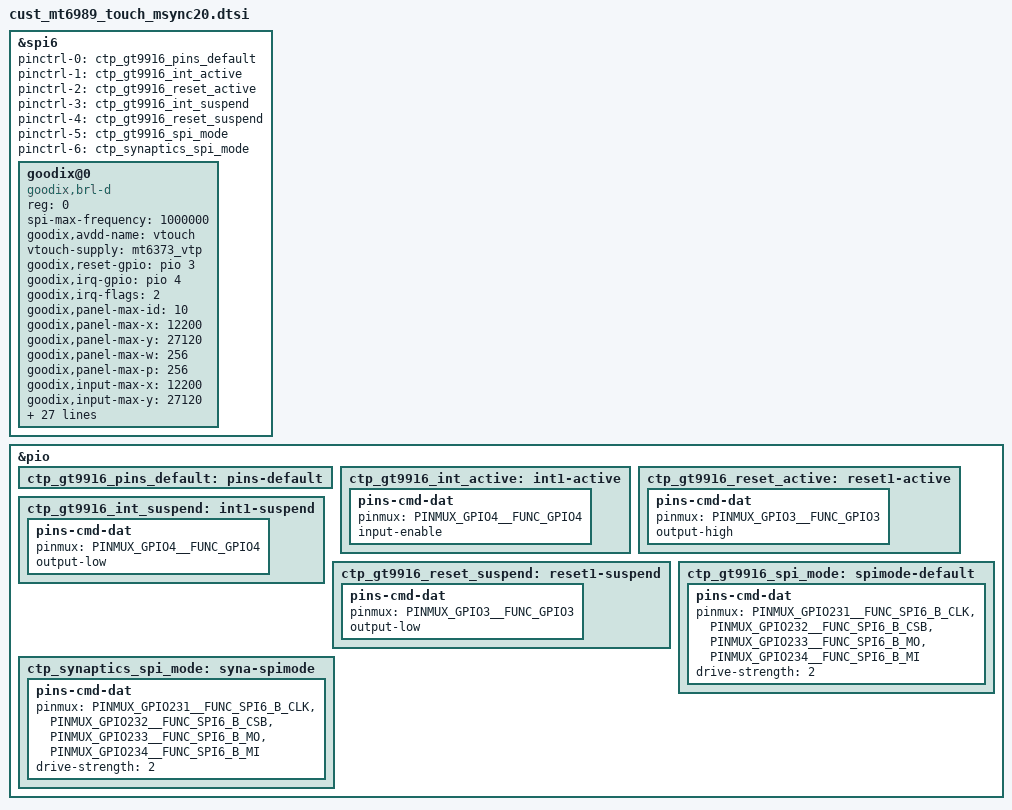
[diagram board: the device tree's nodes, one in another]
// SPDX-License-Identifier: (GPL-2.0 OR MIT)
/*
 * Copyright (C) 2020 MediaTek Inc.
 */

/* TOUCH start */
&spi6 {
	status = "okay";
	#address-cells = <1>;
	#size-cells = <0>;
	pinctrl-names = "default", "gt9916_int_active",
		"gt9916_reset_active", "gt9916_int_suspend",
		"gt9916_reset_suspend", "gt9916_spi_mode",
		"synaptics_spi_mode";
	pinctrl-0 = <&ctp_gt9916_pins_default>;
	pinctrl-1 = <&ctp_gt9916_int_active>;
	pinctrl-2 = <&ctp_gt9916_reset_active>;
	pinctrl-3 = <&ctp_gt9916_int_suspend>;
	pinctrl-4 = <&ctp_gt9916_reset_suspend>;
	pinctrl-5 = <&ctp_gt9916_spi_mode>;
	pinctrl-6 = <&ctp_synaptics_spi_mode>;

	goodix@0 {
		compatible = "goodix,brl-d", "synaptics,tcm-spi";
		reg = <0>; //Same as CS ID
		spi-max-frequency = <1000000>;

		goodix,avdd-name = "vtouch";
		vtouch-supply = <&mt6373_vtp>;
		goodix,reset-gpio = <&pio 3 0x0>;
		goodix,irq-gpio = <&pio 4 0x0>;
		goodix,irq-flags = <2>; /* 1:rising, 2:falling;*/
		goodix,panel-max-id = <10>;
		goodix,panel-max-x = <12200>;
		goodix,panel-max-y = <27120>;
		goodix,panel-max-w = <256>;
		goodix,panel-max-p = <256>;
		goodix,input-max-x = <12200>;
		goodix,input-max-y = <27120>;
		gt9916,power-voltage = <2800000>;
		goodix,panel-key-map = <158 172 217>; /*BACK,HOMEPAGE,SEARCH*/
		goodix,power-on-delay-us = <10000>; /*10ms*/
		goodix,power-off-delay-us = <5000>;
		gt9916,firmware-name = "gt9916_L12_firmware_6985v01.bin";
		gt9916,config-name = "gt9916_L12_cfg_6985v01.bin";
		goodix,firmware-version = "6983v01";
		goodix,config-version = "6983v01";
		/*goodix,swap-axis;*/
		/*gt9916,x2x;*/
		/*gt9916,y2y;*/
		goodix,x2x;
		goodix,y2y;
		goodix,pen-enable;
		tpd-filter-enable = <0>;
		tpd-filter-pixel-density = <161>;
		tpd-filter-custom-prameters = <0 0 0 0 0 0 0 0 0 0 0 0>;
		tpd-filter-custom-speed = <0 0 0>;
		synaptics,pwr-reg-name = "vtouch";
		synaptics,irq-gpio = <&pio 4 0x2008>;
		synaptics,reset-gpio = <&pio 3 0x0>;
		synaptics,irq-flags = <2>; /* 1:rising, 2:falling;*/
		synaptics,irq-on-state = <0>;
		synaptics,reset-on-state = <0>;
		synaptics,power-on-state = <1>;
		synaptics,reset-active-ms = <20>;
		synaptics,reset-delay-ms = <30>;
		synaptics,power-delay-ms = <60>;
	};

};

&pio {
	ctp_gt9916_pins_default: pins-default {
	};
	ctp_gt9916_int_active: int1-active {
		pins-cmd-dat {
			pinmux = <PINMUX_GPIO4__FUNC_GPIO4>;
			input-enable;
		};
	};
	ctp_gt9916_reset_active: reset1-active {
		pins-cmd-dat {
			pinmux = <PINMUX_GPIO3__FUNC_GPIO3>;
			output-high;
		};
	};
	ctp_gt9916_int_suspend: int1-suspend {
		pins-cmd-dat {
			pinmux = <PINMUX_GPIO4__FUNC_GPIO4>;
			output-low;
		};
	};
	ctp_gt9916_reset_suspend: reset1-suspend {
		pins-cmd-dat {
			pinmux = <PINMUX_GPIO3__FUNC_GPIO3>;
			output-low;
		};
	};
	ctp_gt9916_spi_mode: spimode-default {
		pins-cmd-dat {
			pinmux = <PINMUX_GPIO231__FUNC_SPI6_B_CLK>,
				<PINMUX_GPIO232__FUNC_SPI6_B_CSB>,
				<PINMUX_GPIO233__FUNC_SPI6_B_MO>,
				<PINMUX_GPIO234__FUNC_SPI6_B_MI>;
			drive-strength = <2>;
		};
	};
	ctp_synaptics_spi_mode: syna-spimode {
		pins-cmd-dat {
			pinmux = <PINMUX_GPIO231__FUNC_SPI6_B_CLK>,
				<PINMUX_GPIO232__FUNC_SPI6_B_CSB>,
				<PINMUX_GPIO233__FUNC_SPI6_B_MO>,
				<PINMUX_GPIO234__FUNC_SPI6_B_MI>;
			drive-strength = <2>;
		};
	};
};
/* TOUCH end */
